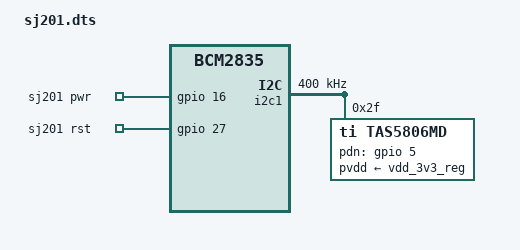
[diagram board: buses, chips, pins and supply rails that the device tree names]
/*
 * Device Tree Overlay for SJ-201 Rev6&10 - XMOS VocalFusion 3510-INT
 *
 * This DTO is designed to configure the hardware interfaces and settings for the SJ-201 board,
 * which uses an I2S interface for audio data and requires specific GPIO pins for power and reset control.
 *
 * Instructions:
 * Compile this DTO with the following command:
 * dtc -@ -H epapr -O dtb -o sj201.dtbo -Wno-unit_address_vs_reg sj201.dts
 */

/dts-v1/;
/plugin/;

/ {
    compatible = "brcm,bcm2835";

    /* Enables the I2S clock producer */
    fragment@0 {
        target = <&i2s_clk_producer>;
        __overlay__ {
            status = "okay";
        };
    };

    /* Configures the TAS5806MD DAC*/
    fragment@1 {
        target = <&i2c1>;
        __overlay__ {
            status = "okay";
            clock-frequency = <400000>;
            #address-cells = <1>;
            #size-cells = <0>;

            tas5806md {
                #sound-dai-cells = <0>;
                compatible = "ti,tas5806md";
                pvdd-supply = <&vdd_3v3_reg>;
                reg = <0x2f>;
                pdn-gpios = <&gpio 5 0>;
            };
        };
    };

    /* Configures GPIO pins for the clock and control */
    fragment@2 {
        target = <&gpio>;
        __overlay__ {
            // Clock pin configuration
            xvf_clk_pin: xvf_clk_pin {
                brcm,pins = <4>;
                brcm,function = <4>; // Set as ALT0 (GPCLK0)
            };
            // Control pins configuration
            xvf_ctrl_pins: xvf_ctrl_pins {
                brcm,pins = <16 27>;
                brcm,function = <1 1>; // Set as output
            };
        };
    };

    /* Configures the XMOS Vocal Fusion 3510-INT*/
    fragment@3 {
        target = <&sound>;
        sj201: __overlay__ {
            compatible = "sj201,sj201-card";
            i2s-controller = <&i2s_clk_producer>;
            status = "okay";

            // Master clock configuration
            clocks = <&clocks 38>;
            clock-names = "mclk";
            clock-frequency = <24576000>; // 24.576 MHz

            // Pin control configuration
            pinctrl-names = "default";
            pinctrl-0 = <&xvf_clk_pin &xvf_ctrl_pins>;

            // GPIO configuration for power and reset
            pwr-gpio = <&gpio 16 0>; // GPIO 16, active high
            rst-gpio = <&gpio 27 0>; // GPIO 27, active high
        };
    };
};
